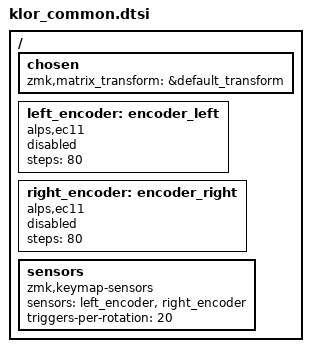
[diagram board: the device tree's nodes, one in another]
/*
 * Copyright (c) 2022 The ZMK Contributors
 *
 * SPDX-License-Identifier: MIT
 */

#include <dt-bindings/zmk/matrix_transform.h>

/ {
	chosen {
		zmk,matrix_transform = &default_transform;
	};

	left_encoder: encoder_left {
		compatible = "alps,ec11";
		steps = <80>;
		status = "disabled";
	};

	right_encoder: encoder_right {
		compatible = "alps,ec11";
		steps = <80>;
		status = "disabled";
	};

	sensors {
		compatible = "zmk,keymap-sensors";
		sensors = <&left_encoder &right_encoder>;
                triggers-per-rotation = <20>;
	};
};
